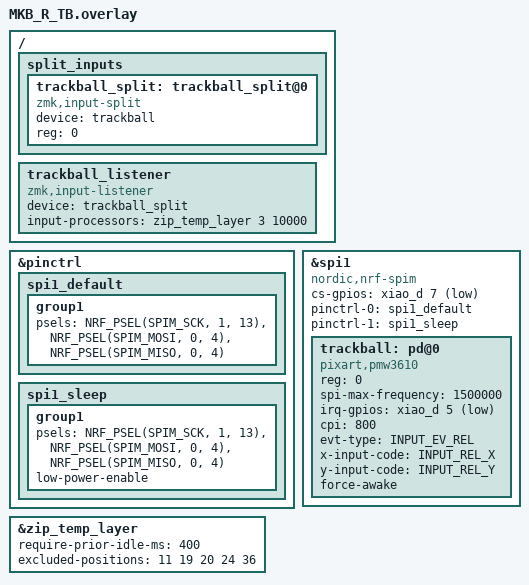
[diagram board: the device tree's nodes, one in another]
#include <input/processors.dtsi>

/* ===================== SPI1 pin config ===================== */
&pinctrl {
    spi1_default: spi1_default {
        group1 {
            psels = <NRF_PSEL(SPIM_SCK,  1, 13)>,
                    <NRF_PSEL(SPIM_MOSI, 0, 4)>,
                    <NRF_PSEL(SPIM_MISO, 0, 4)>;
        };
    };

    spi1_sleep: spi1_sleep {
        group1 {
            psels = <NRF_PSEL(SPIM_SCK,  1, 13)>,
                    <NRF_PSEL(SPIM_MOSI, 0, 4)>,
                    <NRF_PSEL(SPIM_MISO, 0, 4)>;
            low-power-enable;
        };
    };
};

/* ===================== PMW3610 trackball on SPI1 ===================== */
&spi1 {
    status = "okay";
    cs-gpios =  <&xiao_d 7 GPIO_ACTIVE_LOW>;
    pinctrl-0 = <&spi1_default>;
    pinctrl-1 = <&spi1_sleep>;
    pinctrl-names = "default", "sleep";
    compatible = "nordic,nrf-spim";

    trackball: pd@0 {
        status = "okay";
        compatible = "pixart,pmw3610";
        reg = <0>;
        spi-max-frequency = <1500000>;
        irq-gpios = <&xiao_d 5 (GPIO_ACTIVE_LOW | GPIO_PULL_UP)>;
        cpi = <800>;
        evt-type = <INPUT_EV_REL>;
        x-input-code = <INPUT_REL_X>;
        y-input-code = <INPUT_REL_Y>;
        force-awake;
    };
};

/* ===================== AML 動作パラメータ ===================== */
&zip_temp_layer {
    /* キー入力から 400ms 以内は AML を発動しない（誤爆防止を少し強める） */
    require-prior-idle-ms = <400>;

    /* AML 中に押してもレイヤー解除しないキー
     * ; / J / K / Left Shift / Left Ctrl
     */
    excluded-positions = <
        11  /* ; */
        19  /* J */
        20  /* K */
        24  /* Left Shift */
        36  /* Left Ctrl */
    >;
};

/* ===================== input-split + listener ===================== */
/*input-split*/
 / {
    split_inputs {
        #address-cells = <1>;
        #size-cells = <0>;

        trackball_split: trackball_split@0 {
            compatible = "zmk,input-split";
            status = "okay";
            device = <&trackball>;
            reg = <0>;
        };
    };

    trackball_listener: trackball_listener {
        compatible = "zmk,input-listener";
        status = "okay";
        device = <&trackball_split>;

        /* <&zip_temp_layer レイヤー番号 タイムアウト(ms)> */
        /* MOUSE = 3 を 10 秒間オンにする AML */
        input-processors = <&zip_temp_layer 3 10000>;
    };
};
